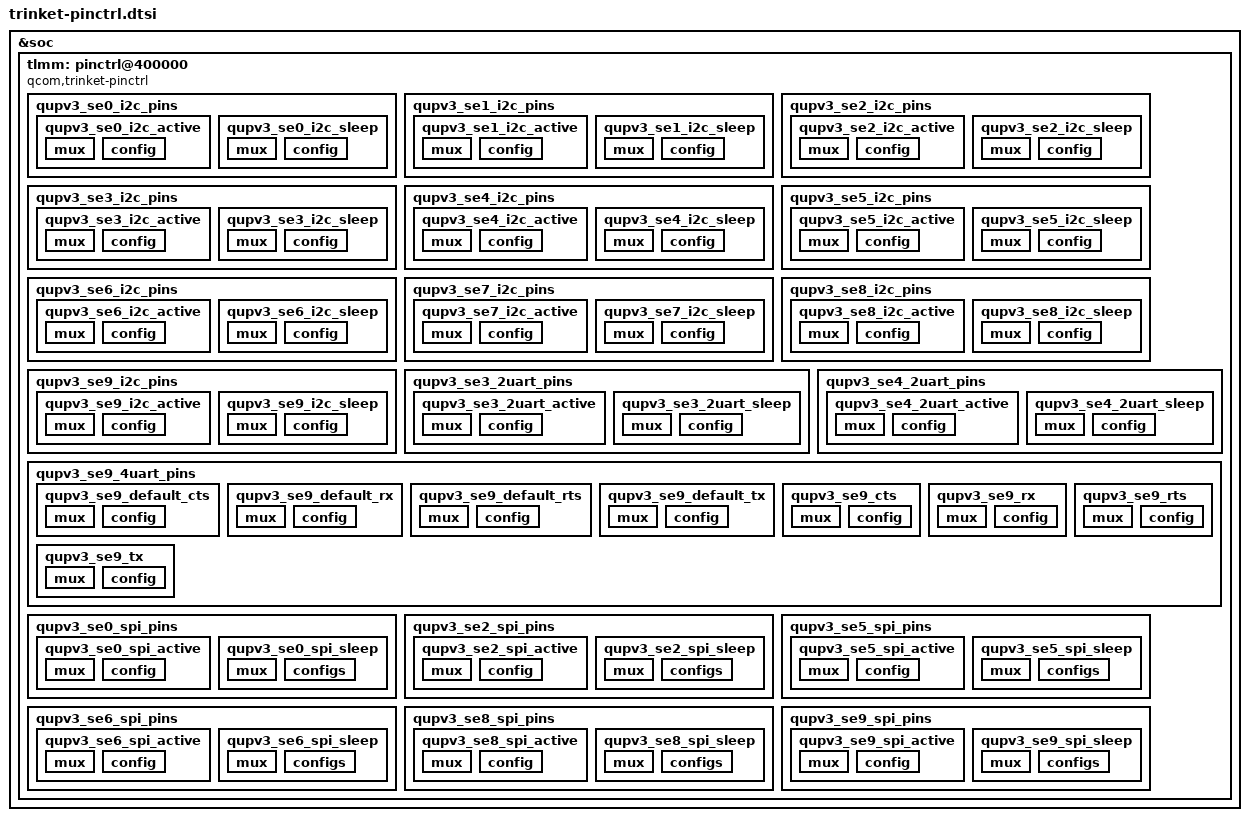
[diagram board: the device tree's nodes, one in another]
&soc {
	tlmm: pinctrl@400000 {
		compatible = "qcom,trinket-pinctrl";
		reg = <0x400000 0xc00000>;
		interrupts = <GIC_SPI 227 IRQ_TYPE_LEVEL_HIGH>;
		gpio-controller;
		#gpio-cells = <2>;
		interrupt-controller;
		#interrupt-cells = <2>;
		wakeup-parent = <&mpm>;
		qcom,gpios-reserved = <0 1 2 3 30 31 32 33>;

		/* QUPv3_0 SE mappings */
		/* SE 0 pin mappings */
		qupv3_se0_i2c_pins: qupv3_se0_i2c_pins {
			qupv3_se0_i2c_active: qupv3_se0_i2c_active {
				mux {
					pins = "gpio0", "gpio1";
					function = "qup00";
				};

				config {
					pins = "gpio0", "gpio1";
					drive-strength = <2>;
					bias-disable;
				};
			};

			qupv3_se0_i2c_sleep: qupv3_se0_i2c_sleep {
				mux {
					pins = "gpio0", "gpio1";
					function = "gpio";
				};

				config {
					pins = "gpio0", "gpio1";
					drive-strength = <2>;
					bias-pull-up;
				};
			};
		};

		/* SE 1 pin mappings */
		qupv3_se1_i2c_pins: qupv3_se1_i2c_pins {
			qupv3_se1_i2c_active: qupv3_se1_i2c_active {
				mux {
					pins = "gpio4", "gpio5";
					function = "qup01";
				};

				config {
					pins = "gpio4", "gpio5";
					drive-strength = <2>;
					bias-disable;
				};
			};

			qupv3_se1_i2c_sleep: qupv3_se1_i2c_sleep {
				mux {
					pins = "gpio4", "gpio5";
					function = "gpio";
				};

				config {
					pins = "gpio4", "gpio5";
					drive-strength = <2>;
					bias-pull-up;
				};
			};
		};

		/* SE 2 pin mappings */
		qupv3_se2_i2c_pins: qupv3_se2_i2c_pins {
			qupv3_se2_i2c_active: qupv3_se2_i2c_active {
				mux {
					pins = "gpio6", "gpio7";
					function = "qup02";
				};

				config {
					pins = "gpio6", "gpio7";
					drive-strength = <2>;
					bias-disable;
				};
			};

			qupv3_se2_i2c_sleep: qupv3_se2_i2c_sleep {
				mux {
					pins = "gpio6", "gpio7";
					function = "gpio";
				};

				config {
					pins = "gpio6", "gpio7";
					drive-strength = <2>;
					bias-pull-up;
				};
			};
		};

		/* SE 3 pin mappings */
		qupv3_se3_i2c_pins: qupv3_se3_i2c_pins {
			qupv3_se3_i2c_active: qupv3_se3_i2c_active {
				mux {
						pins = "gpio14", "gpio15";
						function = "qup03";
				};

				config {
						pins = "gpio14", "gpio15";
						drive-strength = <2>;
						bias-disable;
				};
			};

			qupv3_se3_i2c_sleep: qupv3_se3_i2c_sleep {
				mux {
						pins = "gpio14", "gpio15";
						function = "gpio";
				};

				config {
						pins = "gpio14", "gpio15";
						drive-strength = <2>;
						bias-pull-up;
				};
			};
		};

		/* SE 4 pin mappings */
		qupv3_se4_i2c_pins: qupv3_se4_i2c_pins {
			qupv3_se4_i2c_active: qupv3_se4_i2c_active {
				mux {
						pins = "gpio16", "gpio17";
						function = "qup04";
				};

				config {
						pins = "gpio16", "gpio17";
						drive-strength = <2>;
						bias-disable;
				};
			};

			qupv3_se4_i2c_sleep: qupv3_se4_i2c_sleep {
				mux {
						pins = "gpio16", "gpio17";
						function = "gpio";
				};

				config {
						pins = "gpio16", "gpio17";
						drive-strength = <2>;
						bias-pull-up;
				};
			};
		};

		/*QUPv3_1 SE mappings */
		/* SE 5 pin mappings */
		qupv3_se5_i2c_pins: qupv3_se5_i2c_pins {
			qupv3_se5_i2c_active: qupv3_se5_i2c_active {
				mux {
						pins = "gpio22", "gpio23";
						function = "qup10";
				};

				config {
						pins = "gpio22", "gpio23";
						drive-strength = <2>;
						bias-disable;
				};
			};

			qupv3_se5_i2c_sleep: qupv3_se5_i2c_sleep {
				mux {
						pins = "gpio22", "gpio23";
						function = "gpio";
				};

				config {
						pins = "gpio22", "gpio23";
						drive-strength = <2>;
						bias-pull-up;
				};
			};
		};

		/* SE 6 pin mappings */
		qupv3_se6_i2c_pins: qupv3_se6_i2c_pins {
			qupv3_se6_i2c_active: qupv3_se6_i2c_active {
				mux {
						pins = "gpio30", "gpio31";
						function = "qup11";
				};

				config {
						pins = "gpio30", "gpio31";
						drive-strength = <2>;
						bias-disable;
				};
			};

			qupv3_se6_i2c_sleep: qupv3_se6_i2c_sleep {
				mux {
						pins = "gpio30", "gpio31";
						function = "gpio";
				};

				config {
						pins = "gpio30", "gpio31";
						drive-strength = <2>;
						bias-pull-up;
				};
			};
		};

		/* SE 7 pin mappings */
		qupv3_se7_i2c_pins: qupv3_se7_i2c_pins {
			qupv3_se7_i2c_active: qupv3_se7_i2c_active {
				mux {
						pins = "gpio28", "gpio29";
						function = "qup12";
				};

				config {
						pins = "gpio28", "gpio29";
						drive-strength = <2>;
						bias-disable;
				};
			};

			qupv3_se7_i2c_sleep: qupv3_se7_i2c_sleep {
				mux {
						pins = "gpio28", "gpio29";
						function = "gpio";
				};

				config {
						pins = "gpio28", "gpio29";
						drive-strength = <2>;
						bias-pull-up;
				};
			};
		};

		/* SE 8 pin mappings */
		qupv3_se8_i2c_pins: qupv3_se8_i2c_pins {
			qupv3_se8_i2c_active: qupv3_se8_i2c_active {
				mux {
						pins = "gpio18", "gpio19";
						function = "qup13";
				};

				config {
						pins = "gpio18", "gpio19";
						drive-strength = <2>;
						bias-disable;
				};
			};

			qupv3_se8_i2c_sleep: qupv3_se8_i2c_sleep {
				mux {
						pins = "gpio18", "gpio19";
						function = "gpio";
				};

				config {
						pins = "gpio18", "gpio19";
						drive-strength = <2>;
						bias-pull-up;
				};
			};
		};

		/* SE 9 pin mappings */
		qupv3_se9_i2c_pins: qupv3_se9_i2c_pins {
			qupv3_se9_i2c_active: qupv3_se9_i2c_active {
				mux {
						pins = "gpio10", "gpio11";
						function = "qup14";
				};

				config {
						pins = "gpio10", "gpio11";
						drive-strength = <2>;
						bias-disable;
				};
			};

			qupv3_se9_i2c_sleep: qupv3_se9_i2c_sleep {
				mux {
						pins = "gpio10", "gpio11";
						function = "gpio";
				};

				config {
						pins = "gpio10", "gpio11";
						drive-strength = <2>;
						bias-pull-up;
				};
			};
		};

		qupv3_se3_2uart_pins: qupv3_se3_2uart_pins {
			qupv3_se3_2uart_active: qupv3_se3_2uart_active {
				mux {
					pins = "gpio14", "gpio15";
					function = "qup03";
				};

				config {
					pins = "gpio14", "gpio15";
					drive-strength = <2>;
					bias-disable;
				};
			};

			qupv3_se3_2uart_sleep: qupv3_se3_2uart_sleep {
				mux {
					pins = "gpio14", "gpio15";
					function = "gpio";
				};

				config {
					pins = "gpio14", "gpio15";
					drive-strength = <2>;
					bias-pull-down;
				};
			};
		};

		qupv3_se4_2uart_pins: qupv3_se4_2uart_pins {
			qupv3_se4_2uart_active: qupv3_se4_2uart_active {
				mux {
					pins = "gpio16", "gpio17";
					function = "qup04";
				};

				config {
						pins = "gpio16", "gpio17";
						drive-strength = <2>;
						bias-disable;
				};
			};

			qupv3_se4_2uart_sleep: qupv3_se4_2uart_sleep {
				mux {
						pins = "gpio16", "gpio17";
						function = "gpio";
				};

				config {
						pins = "gpio16", "gpio17";
						drive-strength = <2>;
						bias-pull-down;
				};
			};
		};

		qupv3_se9_4uart_pins: qupv3_se9_4uart_pins {
			qupv3_se9_default_cts: qupv3_se9_default_cts {
				mux {
					pins = "gpio10";
					function = "gpio";
				};

				config {
					pins = "gpio10";
					drive-strength = <2>;
					bias-pull-down;
				};
			};

			qupv3_se9_default_rx: qupv3_se9_default_rx {
				mux {
					pins = "gpio13";
					function = "gpio";
				};

				config {
					pins = "gpio13";
					drive-strength = <2>;
					bias-pull-down;
				};
			};

			qupv3_se9_default_rts: qupv3_se9_default_rts {
				mux {
					pins = "gpio11";
					function = "gpio";
				};

				config {
					pins = "gpio11";
					drive-strength = <2>;
					bias-pull-down;
				};
			};

			qupv3_se9_default_tx: qupv3_se9_default_tx {
				mux {
					pins = "gpio12";
					function = "gpio";
				};

				config {
					pins = "gpio12";
					drive-strength = <2>;
					bias-pull-up;
				};
			};

			qupv3_se9_cts: qupv3_se9_cts {
				mux {
					pins = "gpio10";
					function = "qup14";
				};

				config {
					pins = "gpio10";
					drive-strength = <2>;
					bias-no-pull;
				};
			};

			qupv3_se9_rx: qupv3_se9_rx {
				mux {
					pins = "gpio13";
					function = "qup14";
				};

				config {
					pins = "gpio13";
					drive-strength = <2>;
					bias-no-pull;
				};
			};

			qupv3_se9_rts: qupv3_se9_rts {
				mux {
					pins = "gpio11";
					function = "qup14";
				};

				config {
					pins = "gpio11";
					drive-strength = <2>;
					bias-pull-down;
				};
			};

			qupv3_se9_tx: qupv3_se9_tx {
				mux {
					pins = "gpio12";
					function = "qup14";
				};

				config {
					pins = "gpio12";
					drive-strength = <2>;
					bias-pull-up;
				};
			};
		};

		/* SPI Instances */
		/* SE 0 pin mappings */
		qupv3_se0_spi_pins: qupv3_se0_spi_pins {
			qupv3_se0_spi_active: qupv3_se0_spi_active {
				mux {
					pins = "gpio0", "gpio1", "gpio2",
								"gpio3";
					function = "qup00";
				};

				config {
					pins = "gpio0", "gpio1", "gpio2",
								"gpio3";
					drive-strength = <6>;
					bias-disable;
				};
			};

			qupv3_se0_spi_sleep: qupv3_se0_spi_sleep {
				mux {
					pins = "gpio0", "gpio1", "gpio2",
								"gpio3";
					function = "gpio";
				};

				configs {
					pins = "gpio0", "gpio1", "gpio2",
								"gpio3";
					drive-strength = <6>;
					bias-disable;
				};
			};
		};

		/* SE 2 pin mappings */
		qupv3_se2_spi_pins: qupv3_se2_spi_pins {
			qupv3_se2_spi_active: qupv3_se2_spi_active {
				mux {
					pins = "gpio6", "gpio7", "gpio8",
								"gpio9";
					function = "qup02";
				};

				config {
					pins = "gpio6", "gpio7", "gpio8",
								"gpio9";
					drive-strength = <6>;
					bias-disable;
				};
			};

			qupv3_se2_spi_sleep: qupv3_se2_spi_sleep {
				mux {
					pins = "gpio6", "gpio7", "gpio8",
								"gpio9";
					function = "gpio";
				};

				configs {
					pins = "gpio6", "gpio7", "gpio8",
								"gpio9";
					drive-strength = <6>;
					bias-disable;
				};
			};
		};

		/* SE 5 pin mappings */
		qupv3_se5_spi_pins: qupv3_se5_spi_pins {
			qupv3_se5_spi_active: qupv3_se5_spi_active {
				mux {
					pins = "gpio22", "gpio23", "gpio24",
								"gpio25";
					function = "qup10";
				};

				config {
					pins = "gpio22", "gpio23", "gpio24",
								"gpio25";
					drive-strength = <6>;
					bias-disable;
				};
			};

			qupv3_se5_spi_sleep: qupv3_se5_spi_sleep {
				mux {
					pins = "gpio22", "gpio23", "gpio24",
								"gpio25";
					function = "gpio";
				};

				configs {
					pins = "gpio22", "gpio23", "gpio24",
								"gpio25";
					drive-strength = <6>;
					bias-disable;
				};
			};
		};

		/* SE 6 pin mappings */
		qupv3_se6_spi_pins: qupv3_se6_spi_pins {
			qupv3_se6_spi_active: qupv3_se6_spi_active {
				mux {
					pins = "gpio30", "gpio31", "gpio32",
								"gpio33";
					function = "qup11";
				};

				config {
					pins = "gpio30", "gpio31", "gpio32",
								"gpio33";
					drive-strength = <6>;
					bias-disable;
				};
			};

			qupv3_se6_spi_sleep: qupv3_se6_spi_sleep {
				mux {
					pins = "gpio30", "gpio31", "gpio32",
								"gpio33";
					function = "gpio";
				};

				configs {
					pins = "gpio30", "gpio31", "gpio32",
								"gpio33";
					drive-strength = <6>;
					bias-disable;
				};
			};
		};

		/* SE 8 pin mappings */
		qupv3_se8_spi_pins: qupv3_se8_spi_pins {
			qupv3_se8_spi_active: qupv3_se8_spi_active {
				mux {
					pins = "gpio18", "gpio19", "gpio20",
								"gpio21";
					function = "qup13";
				};

				config {
					pins = "gpio18", "gpio19", "gpio20",
								"gpio21";
					drive-strength = <6>;
					bias-disable;
				};
			};

			qupv3_se8_spi_sleep: qupv3_se8_spi_sleep {
				mux {
					pins = "gpio18", "gpio19", "gpio20",
								"gpio21";
					function = "gpio";
				};

				configs {
					pins = "gpio18", "gpio19", "gpio20",
								"gpio21";
					drive-strength = <6>;
					bias-disable;
				};
			};
		};

		/* SE 9 pin mappings */
		qupv3_se9_spi_pins: qupv3_se9_spi_pins {
			qupv3_se9_spi_active: qupv3_se9_spi_active {
				mux {
					pins = "gpio10", "gpio11", "gpio12",
								"gpio13";
					function = "qup14";
				};

				config {
					pins = "gpio10", "gpio11", "gpio12",
								"gpio13";
					drive-strength = <6>;
					bias-disable;
				};
			};

			qupv3_se9_spi_sleep: qupv3_se9_spi_sleep {
				mux {
					pins = "gpio10", "gpio11", "gpio12",
								"gpio13";
					function = "gpio";
				};

				configs {
					pins = "gpio10", "gpio11", "gpio12",
								"gpio13";
					drive-strength = <6>;
					bias-disable;
				};
			};
		};
	};
};
